VERSION ""

NS_ :

BS_:

BU_:
VAL_TABLE_ ErrorCodes 15 "NoErrors" 14 "TemperatureWarning" 6 "MemoryFailure" 5 "CPUFailure" 4 "PowerFailure" 3 "CANInputMessageFailure" 2 "SteeringAngleFailure" 1 "SensorChipError" 0 "Reserved" ;
VAL_TABLE_ SteeringAngleSensorFailure 65535 "Sensor Failure" ;
VAL_TABLE_ DataRate 4 "20ms" 3 "10ms" 2 "5ms" ;
VAL_TABLE_ BaudRate 4 "500k baud" 3 "250k baud" 2 "125k baud" ;
VAL_TABLE_ Status 1 "Normal" 0 "Programming Mode" ;

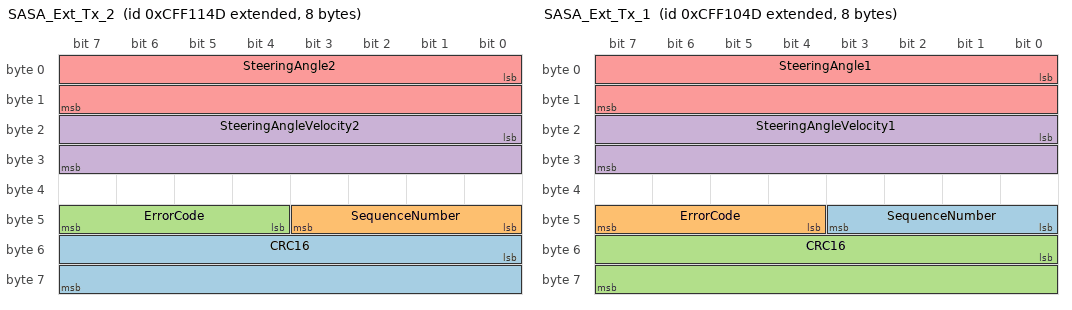
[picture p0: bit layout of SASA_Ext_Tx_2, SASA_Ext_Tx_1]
BO_ 2365526349 SASA_Ext_Tx_2: 8 Vector__XXX
 SG_ CRC16 : 48|16@1+ (1,0) [0|65535] "" Vector__XXX
 SG_ SequenceNumber : 40|4@1+ (1,0) [0|15] "" Vector__XXX
 SG_ ErrorCode : 44|4@1+ (1,0) [0|15] "" Vector__XXX
 SG_ SteeringAngleVelocity2 : 16|16@1+ (0.0146484375,-300) [-300|300] "RPM" Vector__XXX
 SG_ SteeringAngle2 : 0|16@1+ (0.08789059829,0) [0|359.912] "degrees" Vector__XXX

BO_ 2365526093 SASA_Ext_Tx_1: 8 Vector__XXX
 SG_ SequenceNumber : 40|4@1+ (1,0) [0|15] "" Vector__XXX
 SG_ ErrorCode : 44|4@1+ (1,0) [0|15] "" Vector__XXX
 SG_ CRC16 : 48|16@1+ (1,0) [0|65535] "" Vector__XXX
 SG_ SteeringAngleVelocity1 : 16|16@1+ (0.0146484375,-300) [-300|300] "RPM" Vector__XXX
 SG_ SteeringAngle1 : 0|16@1+ (0.08789059829,0) [0|359.912] "degrees" Vector__XXX

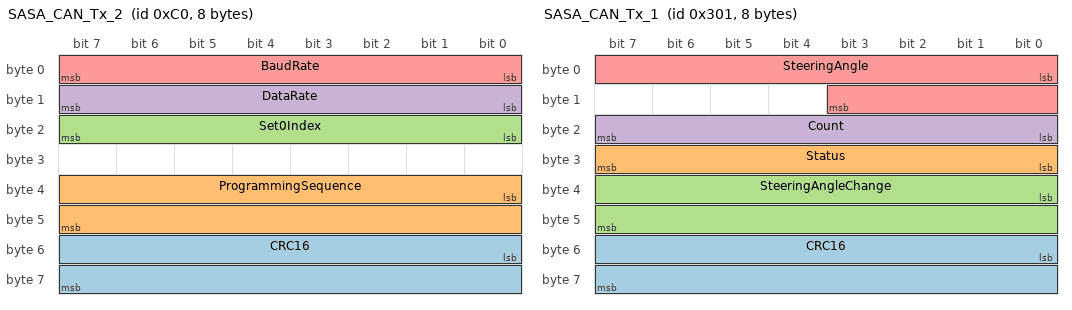
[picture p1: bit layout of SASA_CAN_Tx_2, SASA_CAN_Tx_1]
BO_ 192 SASA_CAN_Tx_2: 8 Vector__XXX
 SG_ CRC16 : 48|16@1+ (1,0) [0|65535] "" Vector__XXX
 SG_ ProgrammingSequence : 32|16@1+ (1,0) [0|65535] "" Vector__XXX
 SG_ Set0Index : 16|8@1+ (1,0) [0|255] "" Vector__XXX
 SG_ DataRate : 8|8@1+ (1,0) [0|255] "" Vector__XXX
 SG_ BaudRate : 0|8@1+ (1,0) [0|0] "" Vector__XXX

BO_ 769 SASA_CAN_Tx_1: 8 Vector__XXX
 SG_ CRC16 : 48|16@1+ (1,0) [0|65535] "" Vector__XXX
 SG_ Status : 24|8@1+ (1,0) [-128|127] "" Vector__XXX
 SG_ SteeringAngleChange : 32|16@1- (0.08789059829,0) [-4096|4095] "degrees" Vector__XXX
 SG_ Count : 16|8@1+ (1,0) [0|255] "" Vector__XXX
 SG_ SteeringAngle : 0|12@1+ (0.08789059829,0) [0|4095] "degrees" Vector__XXX

CM_ SG_ 2365526349 SteeringAngle2 "180 degree offset to Steering angle 1";
CM_ BO_ 2365526093 "The CRC16 polynomial 0xC86C is used to calculate a checksum for byte
0-5.
Width - 16
Init - 0x0000
Ref-In - False
Ref-Out - False
Xor-Out - 0x000
Check - 0x6774";
CM_ SG_ 192 Set0Index "If byte 2 is set to AAh during the programming sequence, the actual angle will be stored as a reference value (0 degree) in persistent memory.";
BA_DEF_ SG_  "SigType" ENUM  "Default","Range","RangeSigned","ASCII","Discrete","Control","ReferencePGN","DTC","StringDelimiter","StringLength","StringLengthControl","MessageCounter","MessageChecksum";
BA_DEF_ SG_  "GenSigEVName" STRING ;
BA_DEF_ SG_  "GenSigILSupport" ENUM  "No","Yes";
BA_DEF_ SG_  "GenSigSendType" ENUM  "Cyclic","OnWrite","OnWriteWithRepetition","OnChange","OnChangeWithRepetition","IfActive","IfActiveWithRepetition","NoSigSendType";
BA_DEF_ SG_  "GenSigStartValue" INT 0 2147483647;
BA_DEF_ BO_  "GenMsgILSupport" ENUM  "No","Yes";
BA_DEF_ BU_  "NmStationAddress" INT 0 255;
BA_DEF_ BO_  "GenMsgSendType" ENUM  "cyclic","NotUsed","IfActive","NotUsed","NotUsed","NotUsed","NotUsed","NotUsed","noMsgSendType";
BA_DEF_ BO_  "GenMsgRequestable" INT 0 1;
BA_DEF_  "DBName" STRING ;
BA_DEF_  "BusType" STRING ;
BA_DEF_  "ProtocolType" STRING ;
BA_DEF_ BO_  "VFrameFormat" ENUM  "StandardCAN","ExtendedCAN","reserved","J1939PG";
BA_DEF_DEF_  "SigType" "Default";
BA_DEF_DEF_  "GenSigEVName" "Env@Nodename_@Signame";
BA_DEF_DEF_  "GenSigILSupport" "Yes";
BA_DEF_DEF_  "GenSigSendType" "NoSigSendType";
BA_DEF_DEF_  "GenSigStartValue" 0;
BA_DEF_DEF_  "GenMsgILSupport" "Yes";
BA_DEF_DEF_  "NmStationAddress" 254;
BA_DEF_DEF_  "GenMsgSendType" "noMsgSendType";
BA_DEF_DEF_  "GenMsgRequestable" 1;
BA_DEF_DEF_  "DBName" "";
BA_DEF_DEF_  "BusType" "CAN";
BA_DEF_DEF_  "ProtocolType" "J1939";
BA_DEF_DEF_  "VFrameFormat" "J1939PG";
BA_ "DBName" "Node_SASA";
BA_ "VFrameFormat" BO_ 2365526349 1;
BA_ "VFrameFormat" BO_ 2365526093 1;
BA_ "VFrameFormat" BO_ 192 0;
BA_ "VFrameFormat" BO_ 769 0;
BA_ "GenSigStartValue" SG_ 2365526349 SteeringAngleVelocity2 20480;
BA_ "GenSigStartValue" SG_ 2365526093 SteeringAngleVelocity1 20480;
VAL_ 2365526349 ErrorCode 15 "NoErrors" 14 "TemperatureWarning" 6 "MemoryFailure" 5 "CPUFailure" 4 "PowerFailure" 3 "CANInputMessageFailure" 2 "SteeringAngleFailure" 1 "SensorChipError" 0 "Reserved" ;
VAL_ 2365526349 SteeringAngleVelocity2 65535 "Sensor Failure" ;
VAL_ 2365526349 SteeringAngle2 65535 "Sensor Failure" ;
VAL_ 2365526093 ErrorCode 15 "NoErrors" 14 "TemperatureWarning" 6 "MemoryFailure" 5 "CPUFailure" 4 "PowerFailure" 3 "CANInputMessageFailure" 2 "SteeringAngleFailure" 1 "SensorChipError" 0 "Reserved" ;
VAL_ 2365526093 SteeringAngleVelocity1 65535 "Sensor Failure" ;
VAL_ 2365526093 SteeringAngle1 65535 "Sensor Failure" ;
VAL_ 192 DataRate 4 "20ms" 3 "10ms" 2 "5ms" ;
VAL_ 192 BaudRate 4 "500k baud" 3 "250k baud" 2 "125k baud" ;
VAL_ 769 Status 1 "Normal" 0 "Programming Mode" ;
